# TC37X register map
File version: 1.0.0
CPU: CM4 r0p1, little endian, MPU, FPU, VTOR, 3 interrupt priority bits
Registers are 16-bit, read-write, reset 0x0 unless marked. A register's access mark holds for its fields unless they carry their own. Offsets are from the block's base; [hi:lo] are bit positions; {n}, {i} and the like mark numbered series; 'fields as' and 'values as' point back to an identical list.

## EVADC — ce_evadc
Base 0xF0020000
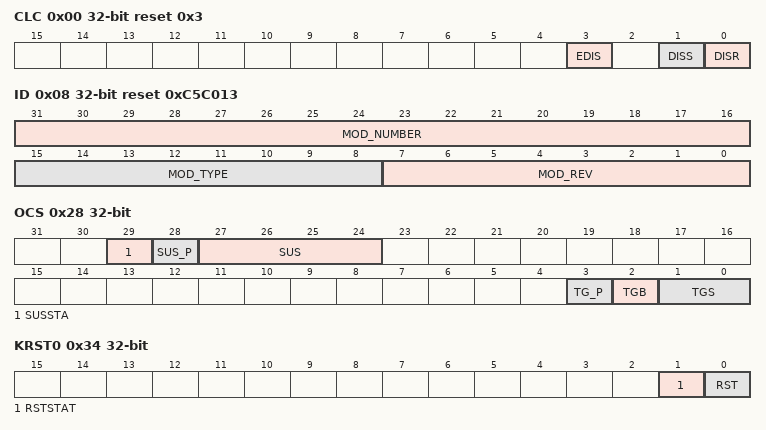
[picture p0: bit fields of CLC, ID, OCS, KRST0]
0x00 CLC 32-bit reset 0x3 — Clock Control Register
  [3] EDIS — Sleep Mode Enable Control - EDIS
  [1] DISS ro — Module Disable Status Bit - DISS
  [0] DISR — Module Disable Request Bit - DISR
0x08 ID 32-bit ro reset 0xC5C013 — Module Identification Register
  [31:16] MOD_NUMBER — Module Number - MOD_NUMBER
  [15:8] MOD_TYPE — Module Type - MOD_TYPE
  [7:0] MOD_REV — Module Revision - MOD_REV
0x28 OCS 32-bit — OCDS Control and Status Register
  [29] SUSSTA ro — Suspend State - SUSSTA
  [28] SUS_P wo — SUS Write Protection - SUS_P
  [27:24] SUS — OCDS Suspend Control - SUS
  [3] TG_P wo — TGS, TGB Write Protection - TG_P
  [2] TGB — OTGB0/1 Bus Select - TGB
  [1:0] TGS — Trigger Set for OTGB0/1 - TGS
0x2C KRSTCLR 32-bit wo — Kernel Reset Status Clear Register
  [0] CLR — Kernel Reset Status Clear - CLR
0x30 KRST1 32-bit — Kernel Reset Register 1
  [0] RST — Kernel Reset - RST
0x34 KRST0 32-bit — Kernel Reset Register 0
  [1] RSTSTAT ro — Kernel Reset Status - RSTSTAT
  [0] RST — Kernel Reset - RST
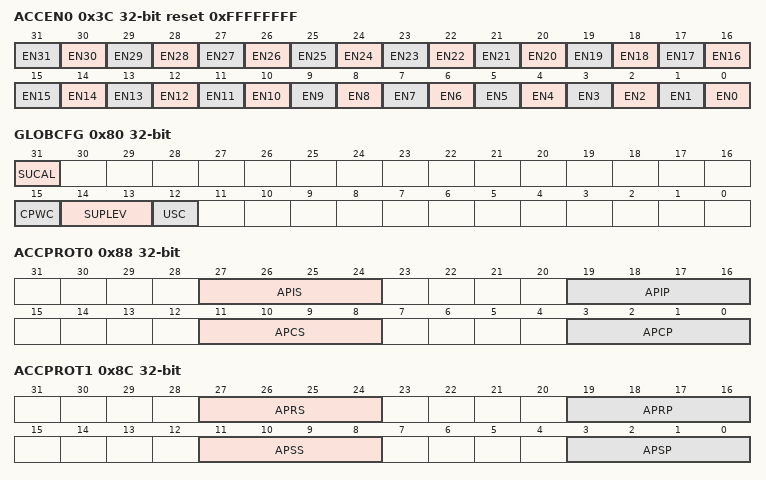
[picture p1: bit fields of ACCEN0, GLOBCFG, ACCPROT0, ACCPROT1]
0x3C ACCEN0 32-bit reset 0xFFFFFFFF — Access Enable Register 0
  [n] EN{n} (n=0..31) — Access Enable for Master TAG ID {n} - EN{n}
0x80 GLOBCFG 32-bit — Global Configuration Register
  [31] SUCAL wo — Start-Up Calibration - SUCAL
  [15] CPWC wo — Write Control for Control Parameters - CPWC
  [14:13] SUPLEV — Supply Voltage Level - SUPLEV
  [12] USC — Unsynchronized Clock Generation - USC
0x88 ACCPROT0 32-bit — Access Protection Register 0
  [27:24] APIS — Access Protection Initialization, Secondary Groups
  [19:16] APIP — Access Protection Initialization, Primary Groups
  [11:8] APCS — Access Protection Channel Control, Secondary Groups
  [3:0] APCP — Access Protection Channel Control, Primary Groups
0x8C ACCPROT1 32-bit — Access Protection Register 1
  [27:24] APRS — Access Protection Result Registers, Secondary Groups
  [19:16] APRP — Access Protection Result Registers, Primary Groups
  [11:8] APSS — Access Protection Service Request, Secondary Groups
  [3:0] APSP — Access Protection Service Request, Primary Groups
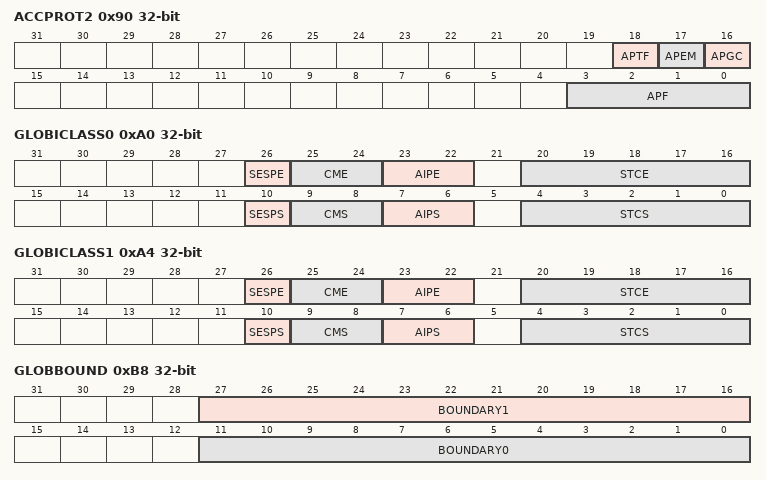
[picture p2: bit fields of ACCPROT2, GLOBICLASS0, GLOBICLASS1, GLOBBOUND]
0x90 ACCPROT2 32-bit — Access Protection Register 2
  [18] APTF — Access Protection Test Function - APTF
  [17] APEM — Access Protection External Multiplexer - APEM
  [16] APGC — Access Protection Global Configuration - APGC
  [3:0] APF — Access Protection Fast Compare Channels
0xA0 GLOBICLASS0 32-bit — Input Class Register 0, Global
  [26] SESPE — Spread Early Sample Point for EMUX Conversions - SESPE
  [25:24] CME — Conversion Mode for EMUX Conversions - CME
  [23:22] AIPE — Analog Input Precharge Control for EMUX Conversions - AIPE
  [20:16] STCE — Sample Time Control for EMUX Conversions - STCE
  [10] SESPS — Spread Early Sample Point for Standard Conversions - SESPS
  [9:8] CMS — Conversion Mode for Standard Conversions - CMS
  [7:6] AIPS — Analog Input Precharge Control for Standard Conversions - AIPS
  [4:0] STCS — Sample Time Control for Standard Conversions - STCS
0xA4 GLOBICLASS1 32-bit — Input Class Register 1, Global
  fields as GLOBICLASS0
0xB8 GLOBBOUND 32-bit — Global Boundary Select Register
  [27:16] BOUNDARY1 — Boundary Value 1 for Limit Checking - BOUNDARY1
  [11:0] BOUNDARY0 — Boundary Value 0 for Limit Checking - BOUNDARY0
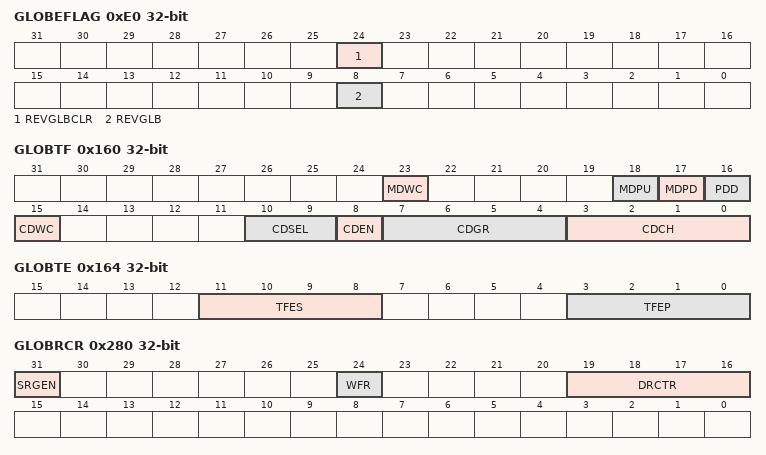
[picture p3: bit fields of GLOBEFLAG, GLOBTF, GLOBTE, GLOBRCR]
0xE0 GLOBEFLAG 32-bit — Global Event Flag Register
  [24] REVGLBCLR wo — Clear Global Result Event - REVGLBCLR
  [8] REVGLB — Global Result Event - REVGLB
0x140 GLOBEVNP 32-bit — Global Event Node Pointer Register
  [19:16] REV0NP — Service Request Node Pointer Global Result
0x160 GLOBTF 32-bit — Global Test Functions Register
  [23] MDWC wo — Write Control for Multiplexer Diagnostics - MDWC
  [18] MDPU — Multiplexer Diagnostics Pull-Up-Devices Enable
  [17] MDPD — Multiplexer Diagnostics Pull-Down-Devices Enable
  [16] PDD — Pull-Down Diagnostics Enable - PDD
  [15] CDWC wo — Write Control for Conversion Diagnostics - CDWC
  [10:9] CDSEL — Converter Diagnostics Pull-Devices Select - CDSEL
  [8] CDEN — Converter Diagnostics Enable - CDEN
  [7:4] CDGR — Conversion Diagnostics Group - CDGR
  [3:0] CDCH — Conversion Diagnostics Channel - CDCH
0x164 GLOBTE 32-bit — Global Test Enable Register
  [11:8] TFES — Test Function Enable, Secondary Groups
  [3:0] TFEP — Test Function Enable, Primary Groups
0x280 GLOBRCR 32-bit — Global Result Control Register
  [31] SRGEN — Service Request Generation Enable - SRGEN
  [24] WFR — Wait-for-Read Mode Enable - WFR
  [19:16] DRCTR — Data Reduction Control - DRCTR
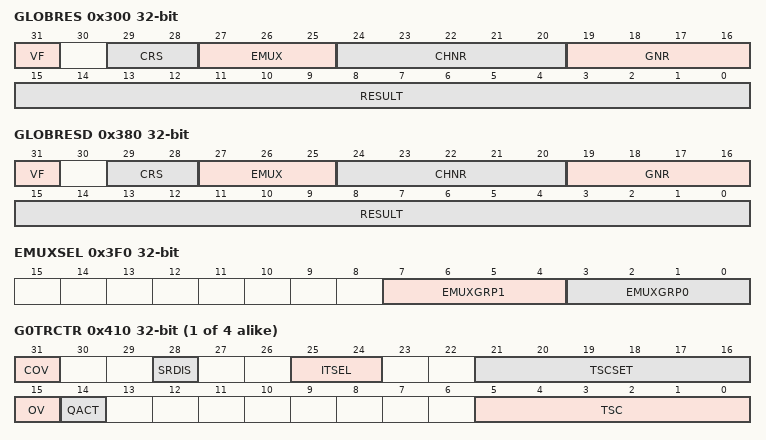
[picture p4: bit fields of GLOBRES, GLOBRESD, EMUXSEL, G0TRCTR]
0x300 GLOBRES 32-bit — Global Result Register
  [31] VF — Valid Flag - VF
  [29:28] CRS ro — Converted Request Source - CRS
  [27:25] EMUX ro — External Multiplexer Setting - EMUX
  [24:20] CHNR ro — Channel Number - CHNR
  [19:16] GNR ro — Group Number - GNR
  [15:0] RESULT — Result of most recent conversion - RESULT
0x380 GLOBRESD 32-bit ro — Global Result Register, Debug
  [31] VF — Valid Flag - VF
  [29:28] CRS — Converted Request Source - CRS
  [27:25] EMUX — External Multiplexer Setting - EMUX
  [24:20] CHNR — Channel Number - CHNR
  [19:16] GNR — Group Number - GNR
  [15:0] RESULT — Result of most recent conversion - RESULT
0x3F0 EMUXSEL 32-bit — External Multiplexer Interface Select Register
  [7:4] EMUXGRP1 — External Multiplexer Group for Interface 1
  [3:0] EMUXGRP0 — External Multiplexer Group for Interface 0
{0x410+0x400*i} G{i}TRCTR 32-bit (i=0..3) — Trigger Control Register, Group {i}
  [31] COV wo — Clear Overflow Flag - COV
  [28] SRDIS — Service Request Disable - SRDIS
  [25:24] ITSEL — Internal Trigger Input Selection - ITSEL
  [21:16] TSCSET — Trigger Sequence Counter Start Value - TSCSET
  [15] OV ro — Overflow Detected - OV
  [14] QACT ro — Queue Active - QACT
  [5:0] TSC ro — Trigger Sequence Counter - TSC
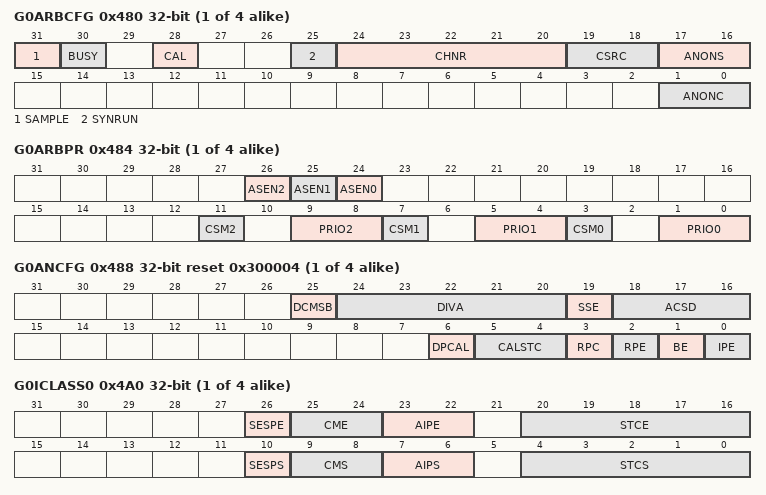
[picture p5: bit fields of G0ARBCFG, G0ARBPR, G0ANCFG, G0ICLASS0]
{0x480+0x400*i} G{i}ARBCFG 32-bit (i=0..3) — Arbitration Config. Register, Group {i}
  [31] SAMPLE ro — Sample Phase Flag - SAMPLE
  [30] BUSY ro — Converter Busy Flag - BUSY
  [28] CAL ro — Start-Up Calibration Active Indication - CAL
  [25] SYNRUN ro — Synchronous Conversion Running - SYNRUN
  [24:20] CHNR ro — Channel Number - CHNR
  [19:18] CSRC ro — Currently Converted Request Source - CSRC
  [17:16] ANONS ro — Analog Converter Control Status - ANONS
  [1:0] ANONC — Analog Converter Control - ANONC
{0x484+0x400*i} G{i}ARBPR 32-bit (i=0..3) — Arbitration Priority Register, Group {i}
  [26] ASEN2 — Arbitration Source Input 2 Enable
  [25] ASEN1 — Arbitration Source Input 1 Enable
  [24] ASEN0 — Arbitration Source Input 0 Enable
  [11] CSM2 — Conversion Start Mode of Request Source 2
  [9:8] PRIO2 — Priority of Request Source i
  [7] CSM1 — Conversion Start Mode of Request Source 1
  [5:4] PRIO1 — Priority of Request Source i
  [3] CSM0 — Conversion Start Mode of Request Source 0
  [1:0] PRIO0 — Priority of Request Source i
{0x488+0x400*i} G{i}ANCFG 32-bit reset 0x300004 (i=0..3) — Analog Fct. Config. Register, Group {i}
  [25] DCMSB — Double Clock for the MSB Conversion - DCMSB
  [24:20] DIVA — Divider Factor for the Analog Internal Clock - DIVA
  [19] SSE — Sample Synchronization Enable - SSE
  [18:16] ACSD — Analog Clock Synchronization Delay - ACSD
  [6] DPCAL — Disable Post-Calibration - DPCAL
  [5:4] CALSTC — Calibration Sample Time Control - CALSTC
  [3] RPC — Reference Precharge Control - RPC
  [2] RPE — Reference Precharge Enable - RPE
  [1] BE — Input Buffer Enable - BE
  [0] IPE — Idle Precharge Enable - IPE
{0x4A0+0x400*i} G{i}ICLASS0 32-bit (i=0..3) — Input Class Register 0, Group {i}
  fields as GLOBICLASS0
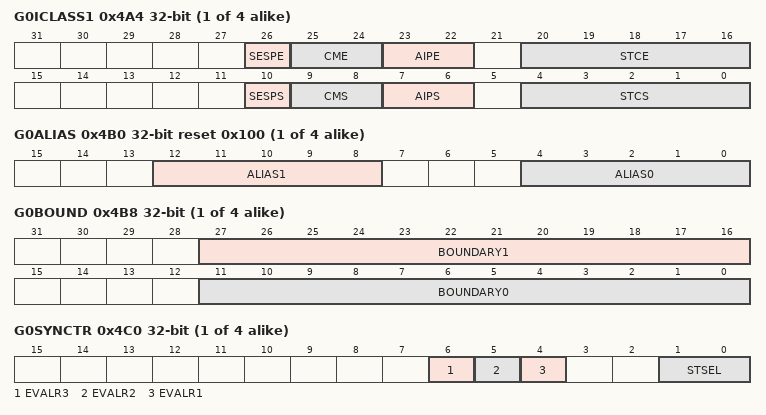
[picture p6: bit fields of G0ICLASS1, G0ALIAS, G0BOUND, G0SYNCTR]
{0x4A4+0x400*i} G{i}ICLASS1 32-bit (i=0..3) — Input Class Register 1, Group {i}
  fields as GLOBICLASS0
{0x4B0+0x400*i} G{i}ALIAS 32-bit reset 0x100 (i=0..3) — Alias Register, Group {i}
  [12:8] ALIAS1 — Alias Value for CH1 Conversion Requests - ALIAS1
  [4:0] ALIAS0 — Alias Value for CH0 Conversion Requests - ALIAS0
{0x4B8+0x400*i} G{i}BOUND 32-bit (i=0..3) — Boundary Select Register, Group {i}
  fields as GLOBBOUND
{0x4C0+0x400*i} G{i}SYNCTR 32-bit (i=0..3) — Synchronization Control Register, Group {i}
  [6] EVALR3 — Evaluate Ready Input Ri
  [5] EVALR2 — Evaluate Ready Input Ri
  [4] EVALR1 — Evaluate Ready Input Ri
  [1:0] STSEL — Start Selection - STSEL
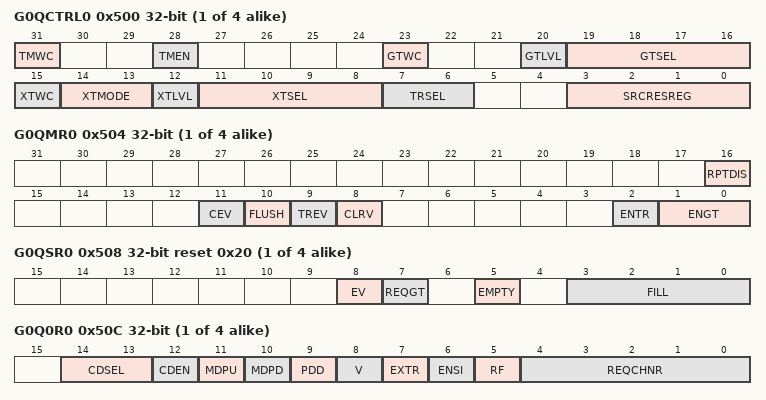
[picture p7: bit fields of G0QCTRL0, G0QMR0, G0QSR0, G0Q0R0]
{0x500+0x400*i} G{i}QCTRL0 32-bit (i=0..3) — Queue 0 Source Contr. Register, Group {i}
  [31] TMWC wo — Write Control for Timer Mode - TMWC
  [28] TMEN — Timer Mode Enable - TMEN
  [23] GTWC wo — Write Control for Gate Configuration - GTWC
  [20] GTLVL ro — Gate Input Level - GTLVL
  [19:16] GTSEL — Gate Input Selection - GTSEL
  [15] XTWC wo — Write Control for Trigger Configuration - XTWC
  [14:13] XTMODE — Trigger Operating Mode - XTMODE
  [12] XTLVL ro — External Trigger Level - XTLVL
  [11:8] XTSEL — External Trigger Input Selection - XTSEL
  [7:6] TRSEL — Trigger Source Selection - TRSEL
  [3:0] SRCRESREG — Source-specific Result Register - SRCRESREG
{0x504+0x400*i} G{i}QMR0 32-bit (i=0..3) — Queue 0 Mode Register, Group {i}
  [16] RPTDIS — Repeat Disable - RPTDIS
  [11] CEV wo — Clear Event Flag - CEV
  [10] FLUSH wo — Flush Queue - FLUSH
  [9] TREV wo — Trigger Event - TREV
  [8] CLRV wo — Clear Valid Bit - CLRV
  [2] ENTR — Enable External Trigger - ENTR
  [1:0] ENGT — Enable Gate - ENGT
{0x508+0x400*i} G{i}QSR0 32-bit ro reset 0x20 (i=0..3) — Queue 0 Status Register, Group {i}
  [8] EV — Event Detected - EV
  [7] REQGT — Request Gate Level - REQGT
  [5] EMPTY — Queue Empty - EMPTY
  [3:0] FILL — Filling Level for Queue - FILL
{0x50C+0x400*i} G{i}Q0R0 32-bit ro (i=0..3) — Queue 0 Register 0, Group {i}
  [14:13] CDSEL — Converter Diagnostics Pull-Devices Select - CDSEL
  [12] CDEN — Converter Diagnostics Enable - CDEN
  [11] MDPU — Multiplexer Diagnostics Pull-Devices Enable - MDPD,MDPU
  [10] MDPD — Multiplexer Diagnostics Pull-Devices Enable - MDPD,MDPU
  [9] PDD — Pull-Down Diagnostics Enable - PDD
  [8] V — Request Channel Number Valid - V
  [7] EXTR — External Trigger - EXTR
  [6] ENSI — Enable Source Interrupt - ENSI
  [5] RF — Refill - RF
  [4:0] REQCHNR — Request Channel Number - REQCHNR
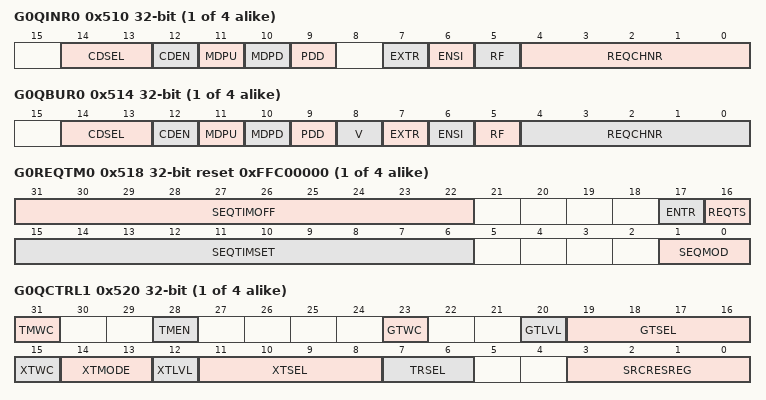
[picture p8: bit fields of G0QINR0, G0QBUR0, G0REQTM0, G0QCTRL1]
{0x510+0x400*i} G{i}QINR0 32-bit wo (i=0..3) — Queue 0 Input Register, Group {i}
  [14:13] CDSEL — Converter Diagnostics Pull-Devices Select - CDSEL
  [12] CDEN — Converter Diagnostics Enable - CDEN
  [11] MDPU — Multiplexer Diagnostics Pull-Devices Enable - MDPD,MDPU
  [10] MDPD — Multiplexer Diagnostics Pull-Devices Enable - MDPD,MDPU
  [9] PDD — Pull-Down Diagnostics Enable - PDD
  [7] EXTR — External Trigger - EXTR
  [6] ENSI — Enable Source Interrupt - ENSI
  [5] RF — Refill - RF
  [4:0] REQCHNR — Request Channel Number - REQCHNR
{0x514+0x400*i} G{i}QBUR0 32-bit ro (i=0..3) — Queue 0 Backup Register, Group {i}
  [14:13] CDSEL — Converter Diagnostics Pull-Devices Select - CDSEL
  [12] CDEN — Converter Diagnostics Enable - CDEN
  [11] MDPU — Multiplexer Diagnostics Pull-Up Devices Enable
  [10] MDPD — Multiplexer Diagnostics Pull-Down Devices Enable
  [9] PDD — Pull-Down Diagnostics Enable - PDD
  [8] V — Request Channel Number Valid - V
  [7] EXTR — External Trigger - EXTR
  [6] ENSI — Enable Source Interrupt - ENSI
  [5] RF — Refill - RF
  [4:0] REQCHNR — Request Channel Number - REQCHNR
{0x518+0x400*i} G{i}REQTM0 32-bit reset 0xFFC00000 (i=0..3) — Queue 0 Requ. Timer Mode Reg., Group {i}
  [31:22] SEQTIMOFF — Sequence Timer, Switch Off Value - SEQTIMOFF
  [17] ENTR — Enable External Trigger - ENTR
  [16] REQTS wo — Request Timer Start Trigger - REQTS
  [15:6] SEQTIMSET — Sequence Timer, Set Value - SEQTIMSET
  [1:0] SEQMOD — Sequence Mode - SEQMOD
{0x51C+0x400*i} G{i}REQTS0 32-bit ro (i=0..3) — Queue 0 Requ. Timer Status Reg., Group {i}
  [15:6] SEQTIMER — Sequence Timer - SEQTIMER
{0x520+0x400*i} G{i}QCTRL1 32-bit (i=0..3) — Queue 1 Source Contr. Register, Group {i}
  fields as G0QCTRL0
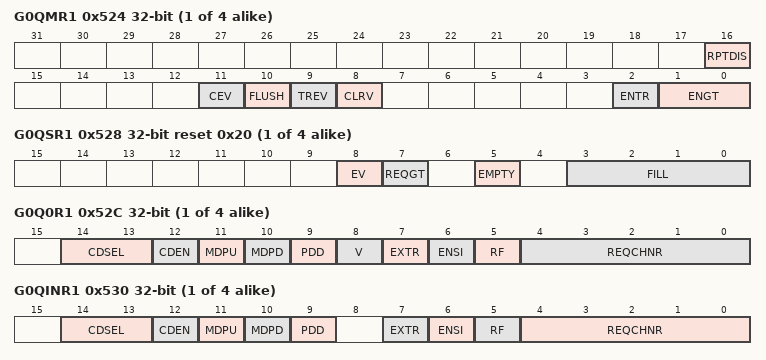
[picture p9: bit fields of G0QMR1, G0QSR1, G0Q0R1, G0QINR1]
{0x524+0x400*i} G{i}QMR1 32-bit (i=0..3) — Queue 1 Mode Register, Group {i}
  fields as G0QMR0
{0x528+0x400*i} G{i}QSR1 32-bit ro reset 0x20 (i=0..3) — Queue 1 Status Register, Group {i}
  fields as G0QSR0
{0x52C+0x400*i} G{i}Q0R1 32-bit ro (i=0..3) — Queue 1 Register 0, Group {i}
  fields as G0Q0R0
{0x530+0x400*i} G{i}QINR1 32-bit wo (i=0..3) — Queue 1 Input Register, Group {i}
  fields as G0QINR0
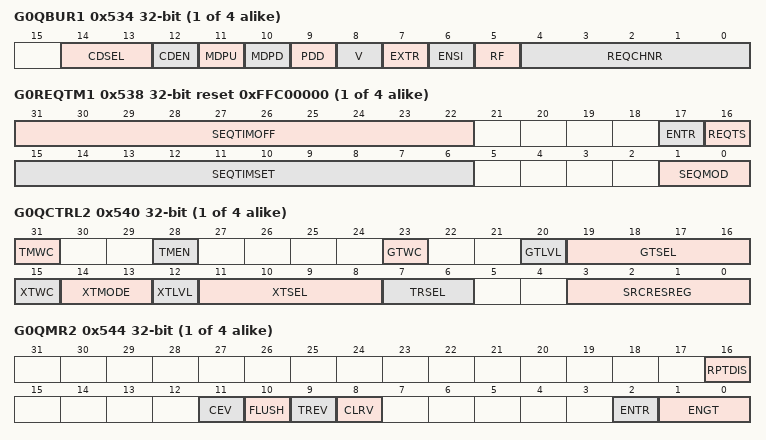
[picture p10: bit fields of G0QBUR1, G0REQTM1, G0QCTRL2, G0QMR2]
{0x534+0x400*i} G{i}QBUR1 32-bit ro (i=0..3) — Queue 1 Backup Register, Group {i}
  fields as G0QBUR0
{0x538+0x400*i} G{i}REQTM1 32-bit reset 0xFFC00000 (i=0..3) — Queue 1 Requ. Timer Mode Reg., Group {i}
  fields as G0REQTM0
{0x53C+0x400*i} G{i}REQTS1 32-bit ro (i=0..3) — Queue 1 Requ. Timer Status Reg., Group {i}
  [15:6] SEQTIMER — Sequence Timer - SEQTIMER
{0x540+0x400*i} G{i}QCTRL2 32-bit (i=0..3) — Queue 2 Source Contr. Register, Group {i}
  fields as G0QCTRL0
{0x544+0x400*i} G{i}QMR2 32-bit (i=0..3) — Queue 2 Mode Register, Group {i}
  fields as G0QMR0
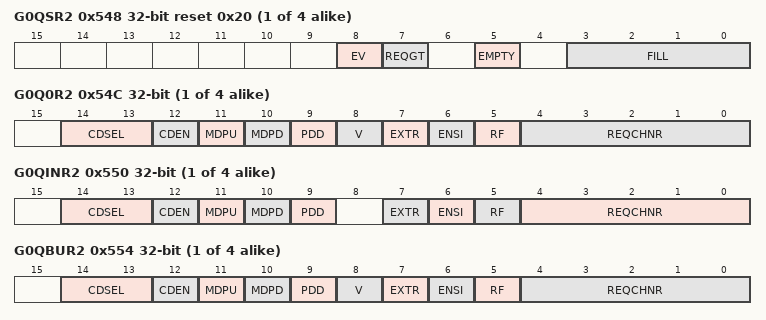
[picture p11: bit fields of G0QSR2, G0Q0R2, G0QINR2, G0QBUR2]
{0x548+0x400*i} G{i}QSR2 32-bit ro reset 0x20 (i=0..3) — Queue 2 Status Register, Group {i}
  fields as G0QSR0
{0x54C+0x400*i} G{i}Q0R2 32-bit ro (i=0..3) — Queue 2 Register 0, Group {i}
  fields as G0Q0R0
{0x550+0x400*i} G{i}QINR2 32-bit wo (i=0..3) — Queue 2 Input Register, Group {i}
  fields as G0QINR0
{0x554+0x400*i} G{i}QBUR2 32-bit ro (i=0..3) — Queue 2 Backup Register, Group {i}
  fields as G0QBUR0
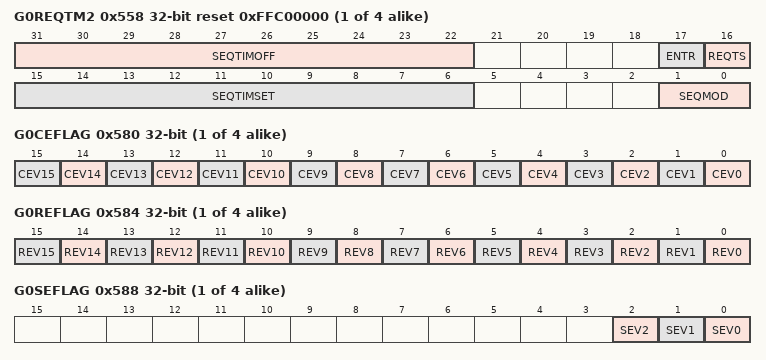
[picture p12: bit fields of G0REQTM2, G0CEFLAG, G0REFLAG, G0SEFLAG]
{0x558+0x400*i} G{i}REQTM2 32-bit reset 0xFFC00000 (i=0..3) — Queue 2 Requ. Timer Mode Reg., Group {i}
  fields as G0REQTM0
{0x55C+0x400*i} G{i}REQTS2 32-bit ro (i=0..3) — Queue 2 Requ. Timer Status Reg., Group {i}
  [15:6] SEQTIMER — Sequence Timer - SEQTIMER
{0x580+0x400*i} G{i}CEFLAG 32-bit (i=0..3) — Channel Event Flag Register, Group {i}
  [n] CEV{n} (n=0..15) — Channel Event for Channel {n}
{0x584+0x400*i} G{i}REFLAG 32-bit (i=0..3) — Result Event Flag Register, Group {i}
  [n] REV{n} (n=0..15) — Result Event for Result Register {n}
{0x588+0x400*i} G{i}SEFLAG 32-bit (i=0..3) — Source Event Flag Register, Group {i}
  [2] SEV2 — Source Event i
  [1] SEV1 — Source Event i
  [0] SEV0 — Source Event i
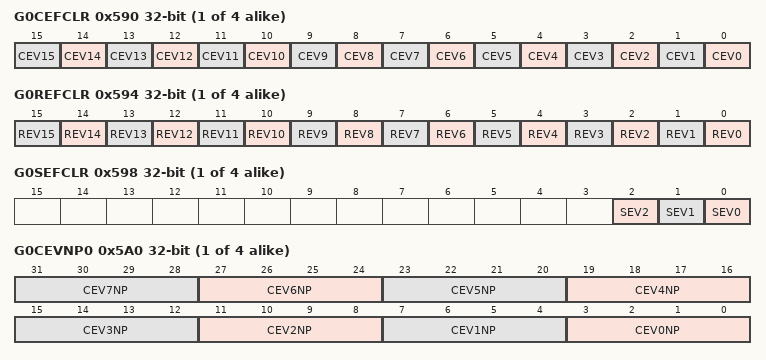
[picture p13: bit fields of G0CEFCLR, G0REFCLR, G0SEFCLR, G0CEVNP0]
{0x590+0x400*i} G{i}CEFCLR 32-bit wo (i=0..3) — Channel Event Flag Clear Register, Group {i}
  [n] CEV{n} (n=0..15) — Clear Channel Event for Channel {n} - CEV{n}
{0x594+0x400*i} G{i}REFCLR 32-bit wo (i=0..3) — Result Event Flag Clear Register, Group {i}
  [n] REV{n} (n=0..15) — Clear Result Event for Result Register {n}
{0x598+0x400*i} G{i}SEFCLR 32-bit wo (i=0..3) — Source Event Flag Clear Reg., Group {i}
  [2] SEV2 — Clear Source Event i
  [1] SEV1 — Clear Source Event i
  [0] SEV0 — Clear Source Event i
{0x5A0+0x400*i} G{i}CEVNP0 32-bit (i=0..3) — Channel Event Node Pointer Reg. 0, Group {i}
  [4n+3:4n] CEV{n}NP (n=0..7) — Service Request Node Pointer Channel Event i
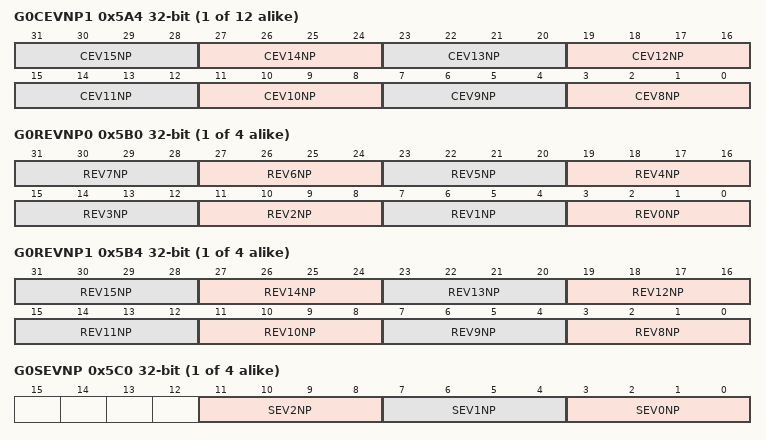
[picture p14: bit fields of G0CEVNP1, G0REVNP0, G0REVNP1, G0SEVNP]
{0x5A4+0x400*i} G{i}CEVNP1 32-bit (i=0..11) — Channel Event Node Pointer Reg. 1, Group {i}
  [4n-29:4n-32] CEV{n}NP (n=8..15) — Service Request Node Pointer Channel Event i
{0x5B0+0x400*i} G{i}REVNP0 32-bit (i=0..3) — Result Event Node Pointer Reg. 0, Group {i}
  [4n+3:4n] REV{n}NP (n=0..7) — Service Request Node Pointer Result Event i
{0x5B4+0x400*i} G{i}REVNP1 32-bit (i=0..3) — Result Event Node Pointer Reg. 1, Group {i}
  [4n-29:4n-32] REV{n}NP (n=8..15) — Service Request Node Pointer Result Event i
{0x5C0+0x400*i} G{i}SEVNP 32-bit (i=0..3) — Source Event Node Pointer Reg., Group {i}
  [11:8] SEV2NP — Service Request Node Pointer Source Event i
  [7:4] SEV1NP — Service Request Node Pointer Source Event i
  [3:0] SEV0NP — Service Request Node Pointer Source Event i
{0x5C8+0x400*i} G{i}SRACT 32-bit wo (i=0..3) — Service Request Software Activation Trigger, Group {i}
  [n+8] ASSR{n} (n=0..3) — Activate Shared Service Request Node {n} - ASSR{n}
  [n] AGSR{n} (n=0..3) — Activate Group Service Request Node {n} - AGSR{n}
{0x5F0+0x400*i} G{i}EMUXCTR 32-bit (i=0..3) — External Multiplexer Control Reg., Group {i}
  [24:20] EMUXCCB — External Multiplexer Channel Selection for Block Mode - EMUXCCB
  [18:16] EMUXACT ro — External Multiplexer Actual Selection - EMUXACT
  [15] EMXWC wo — Write Control for EMUX Configuration - EMXWC
  [14] EMXCSS — External Multiplexer Channel Selection Style - EMXCSS
  [13] EMXST — External Multiplexer Sample Time Control - EMXST
  [12] EMXCOD — External Multiplexer Coding Scheme - EMXCOD
  [6:4] EMUXMODE — External Multiplexer Mode - EMUXMODE
  [2:0] EMUXSET — External Multiplexer Start Selection - EMUXSET
{0x5F4+0x400*i} G{i}EMUXCS 32-bit (i=0..3) — Ext. Multiplexer Channel Select Reg., Group {i}
  [15:0] EMUXCH — External Multiplexer Channel Select - EMUXCH
{0x5F8+0x400*i} G{i}VFR 32-bit (i=0..3) — Valid Flag Register, Group {i}
  [n] VF{n} (n=0..15) — Valid Flag of Result Register x - VF{n}
{0x600+4i} G0CHCTR{i} 32-bit (i=0..7) — Group 0, Channel {i} Control Register
  [30] BWDEN — Broken Wire Detection Enable - BWDEN
  [29:28] BWDCH — Broken Wire Detection Channel - BWDCH
  [21] RESPOS — Result Position - RESPOS
  [20] RESTGT — Result Target - RESTGT
  [19:16] RESREG — Result Register - RESREG
  [15:12] BNDSELX — BoundaryExtension - BNDSELX
  [11] REFSEL — Reference Input Selection - REFSEL
  [10] SYNC — Synchronization Request - SYNC
  [9:8] CHEVMODE — Channel Event Mode - CHEVMODE
  [7:6] BNDSELU — Upper Boundary Select - BNDSELU
  [5:4] BNDSELL — Lower Boundary Select - BNDSELL
  [1:0] ICLSEL — Input Class Select - ICLSEL
{0x680+4i} G0RCR{i} 32-bit (i=0..15) — Group 0 Result Control Register {i}
  [31] SRGEN — Service Request Generation Enable - SRGEN
  [26:25] FEN — FIFO Mode Enable - FEN
  [24] WFR — Wait-for-Read Mode Enable - WFR
  [21:20] DMM — Data Modification Mode - DMM
  [19:16] DRCTR — Data Reduction Control - DRCTR
{0x700+4i} G0RES{i} 32-bit (i=0..15) — Group 0 Result Register {i}
  [31] VF ro — Valid Flag - VF
  [29:28] CRS ro — Converted Request Source - CRS
  [27:25] EMUX ro — External Multiplexer Setting - EMUX
  [24:20] CHNR ro — Channel Number - CHNR
  [19:16] DRC ro — Data Reduction Counter - DRC
  [15:0] RESULT — Result of Most Recent Conversion - RESULT
{0x780+4i} G0RESD{i} 32-bit ro (i=0..15) — Group 0 Result Reg. {i}, Debug
  [31] VF — Valid Flag - VF
  [29:28] CRS — Converted Request Source - CRS
  [27:25] EMUX — External Multiplexer Setting - EMUX
  [24:20] CHNR — Channel Number - CHNR
  [19:16] DRC — Data Reduction Counter - DRC
  [15:0] RESULT — Result of Most Recent Conversion - RESULT
{0xA00+4i} G1CHCTR{i} 32-bit (i=0..7) — Group 1, Channel {i} Control Register
  fields as G0CHCTR0
{0xA80+4i} G1RCR{i} 32-bit (i=0..15) — Group 1 Result Control Register {i}
  fields as G0RCR0
{0xB00+4i} G1RES{i} 32-bit (i=0..15) — Group 1 Result Register {i}
  fields as G0RES0
{0xB80+4i} G1RESD{i} 32-bit ro (i=0..15) — Group 1 Result Reg. {i}, Debug
  fields as G0RESD0
{0xE00+4i} G2CHCTR{i} 32-bit (i=0..7) — Group 2, Channel {i} Control Register
  fields as G0CHCTR0
{0xE80+4i} G2RCR{i} 32-bit (i=0..15) — Group 2 Result Control Register {i}
  fields as G0RCR0
{0xF00+4i} G2RES{i} 32-bit (i=0..15) — Group 2 Result Register {i}
  fields as G0RES0
{0xF80+4i} G2RESD{i} 32-bit ro (i=0..15) — Group 2 Result Reg. {i}, Debug
  fields as G0RESD0
{0x1200+4i} G3CHCTR{i} 32-bit (i=0..7) — Group 3, Channel {i} Control Register
  fields as G0CHCTR0
{0x1280+4i} G3RCR{i} 32-bit (i=0..15) — Group 3 Result Control Register {i}
  fields as G0RCR0
{0x1300+4i} G3RES{i} 32-bit (i=0..15) — Group 3 Result Register {i}
  fields as G0RES0
{0x1380+4i} G3RESD{i} 32-bit ro (i=0..15) — Group 3 Result Reg. {i}, Debug
  fields as G0RESD0
{0x410+0x400*i} G{i}TRCTR 32-bit (i=8..11) — Trigger Control Register, Group {i}
  fields as G0TRCTR
{0x480+0x400*i} G{i}ARBCFG 32-bit (i=8..11) — Arbitration Config. Register, Group {i}
  fields as G0ARBCFG
{0x484+0x400*i} G{i}ARBPR 32-bit (i=8..11) — Arbitration Priority Register, Group {i}
  fields as G0ARBPR
{0x488+0x400*i} G{i}ANCFG 32-bit reset 0x300004 (i=8..11) — Analog Fct. Config. Register, Group {i}
  fields as G0ANCFG
{0x4A0+0x400*i} G{i}ICLASS0 32-bit (i=8..11) — Input Class Register 0, Group {i}
  fields as GLOBICLASS0
{0x4A4+0x400*i} G{i}ICLASS1 32-bit (i=8..11) — Input Class Register 1, Group {i}
  fields as GLOBICLASS0
{0x4B0+0x400*i} G{i}ALIAS 32-bit reset 0x100 (i=8..11) — Alias Register, Group {i}
  fields as G0ALIAS
{0x4B8+0x400*i} G{i}BOUND 32-bit (i=8..11) — Boundary Select Register, Group {i}
  fields as GLOBBOUND
{0x4C0+0x400*i} G{i}SYNCTR 32-bit (i=8..11) — Synchronization Control Register, Group {i}
  fields as G0SYNCTR
{0x500+0x400*i} G{i}QCTRL0 32-bit (i=8..11) — Queue 0 Source Contr. Register, Group {i}
  fields as G0QCTRL0
{0x504+0x400*i} G{i}QMR0 32-bit (i=8..11) — Queue 0 Mode Register, Group {i}
  fields as G0QMR0
{0x508+0x400*i} G{i}QSR0 32-bit ro reset 0x20 (i=8..11) — Queue 0 Status Register, Group {i}
  fields as G0QSR0
{0x50C+0x400*i} G{i}Q0R0 32-bit ro (i=8..11) — Queue 0 Register 0, Group {i}
  fields as G0Q0R0
{0x510+0x400*i} G{i}QINR0 32-bit wo (i=8..11) — Queue 0 Input Register, Group {i}
  fields as G0QINR0
{0x514+0x400*i} G{i}QBUR0 32-bit ro (i=8..11) — Queue 0 Backup Register, Group {i}
  fields as G0QBUR0
{0x518+0x400*i} G{i}REQTM0 32-bit reset 0xFFC00000 (i=8..11) — Queue 0 Requ. Timer Mode Reg., Group {i}
  fields as G0REQTM0
{0x51C+0x400*i} G{i}REQTS0 32-bit ro (i=8..11) — Queue 0 Requ. Timer Status Reg., Group {i}
  [15:6] SEQTIMER — Sequence Timer - SEQTIMER
{0x520+0x400*i} G{i}QCTRL1 32-bit (i=8..11) — Queue 1 Source Contr. Register, Group {i}
  fields as G0QCTRL0
{0x524+0x400*i} G{i}QMR1 32-bit (i=8..11) — Queue 1 Mode Register, Group {i}
  fields as G0QMR0
{0x528+0x400*i} G{i}QSR1 32-bit ro reset 0x20 (i=8..11) — Queue 1 Status Register, Group {i}
  fields as G0QSR0
{0x52C+0x400*i} G{i}Q0R1 32-bit ro (i=8..11) — Queue 1 Register 0, Group {i}
  fields as G0Q0R0
{0x530+0x400*i} G{i}QINR1 32-bit wo (i=8..11) — Queue 1 Input Register, Group {i}
  fields as G0QINR0
{0x534+0x400*i} G{i}QBUR1 32-bit ro (i=8..11) — Queue 1 Backup Register, Group {i}
  fields as G0QBUR0
{0x538+0x400*i} G{i}REQTM1 32-bit reset 0xFFC00000 (i=8..11) — Queue 1 Requ. Timer Mode Reg., Group {i}
  fields as G0REQTM0
{0x53C+0x400*i} G{i}REQTS1 32-bit ro (i=8..11) — Queue 1 Requ. Timer Status Reg., Group {i}
  [15:6] SEQTIMER — Sequence Timer - SEQTIMER
{0x540+0x400*i} G{i}QCTRL2 32-bit (i=8..11) — Queue 2 Source Contr. Register, Group {i}
  fields as G0QCTRL0
{0x544+0x400*i} G{i}QMR2 32-bit (i=8..11) — Queue 2 Mode Register, Group {i}
  fields as G0QMR0
{0x548+0x400*i} G{i}QSR2 32-bit ro reset 0x20 (i=8..11) — Queue 2 Status Register, Group {i}
  fields as G0QSR0
{0x54C+0x400*i} G{i}Q0R2 32-bit ro (i=8..11) — Queue 2 Register 0, Group {i}
  fields as G0Q0R0
{0x550+0x400*i} G{i}QINR2 32-bit wo (i=8..11) — Queue 2 Input Register, Group {i}
  fields as G0QINR0
{0x554+0x400*i} G{i}QBUR2 32-bit ro (i=8..11) — Queue 2 Backup Register, Group {i}
  fields as G0QBUR0
{0x558+0x400*i} G{i}REQTM2 32-bit reset 0xFFC00000 (i=8..11) — Queue 2 Requ. Timer Mode Reg., Group {i}
  fields as G0REQTM0
{0x55C+0x400*i} G{i}REQTS2 32-bit ro (i=8..11) — Queue 2 Requ. Timer Status Reg., Group {i}
  [15:6] SEQTIMER — Sequence Timer - SEQTIMER
{0x580+0x400*i} G{i}CEFLAG 32-bit (i=8..11) — Channel Event Flag Register, Group {i}
  [n] CEV{n} (n=0..15) — Channel Event for Channel {n}
{0x584+0x400*i} G{i}REFLAG 32-bit (i=8..11) — Result Event Flag Register, Group {i}
  [n] REV{n} (n=0..15) — Result Event for Result Register {n}
{0x588+0x400*i} G{i}SEFLAG 32-bit (i=8..11) — Source Event Flag Register, Group {i}
  fields as G0SEFLAG
{0x590+0x400*i} G{i}CEFCLR 32-bit wo (i=8..11) — Channel Event Flag Clear Register, Group {i}
  [n] CEV{n} (n=0..15) — Clear Channel Event for Channel {n} - CEV{n}
{0x594+0x400*i} G{i}REFCLR 32-bit wo (i=8..11) — Result Event Flag Clear Register, Group {i}
  [n] REV{n} (n=0..15) — Clear Result Event for Result Register {n}
{0x598+0x400*i} G{i}SEFCLR 32-bit wo (i=8..11) — Source Event Flag Clear Reg., Group {i}
  fields as G0SEFCLR
{0x5A0+0x400*i} G{i}CEVNP0 32-bit (i=8..11) — Channel Event Node Pointer Reg. 0, Group {i}
  fields as G0CEVNP0
{0x5B0+0x400*i} G{i}REVNP0 32-bit (i=8..11) — Result Event Node Pointer Reg. 0, Group {i}
  fields as G0REVNP0
{0x5B4+0x400*i} G{i}REVNP1 32-bit (i=8..11) — Result Event Node Pointer Reg. 1, Group {i}
  fields as G0REVNP1
{0x5C0+0x400*i} G{i}SEVNP 32-bit (i=8..11) — Source Event Node Pointer Reg., Group {i}
  fields as G0SEVNP
{0x5C8+0x400*i} G{i}SRACT 32-bit wo (i=8..11) — Service Request Software Activation Trigger, Group {i}
  fields as G0SRACT
{0x5F0+0x400*i} G{i}EMUXCTR 32-bit (i=8..11) — External Multiplexer Control Reg., Group {i}
  fields as G0EMUXCTR
{0x5F4+0x400*i} G{i}EMUXCS 32-bit (i=8..11) — Ext. Multiplexer Channel Select Reg., Group {i}
  [15:0] EMUXCH — External Multiplexer Channel Select - EMUXCH
{0x5F8+0x400*i} G{i}VFR 32-bit (i=8..11) — Valid Flag Register, Group {i}
  [n] VF{n} (n=0..15) — Valid Flag of Result Register x - VF{n}
{0x2600+4i} G8CHCTR{i} 32-bit (i=0..15) — Group 8, Channel {i} Control Register
  fields as G0CHCTR0
{0x2680+4i} G8RCR{i} 32-bit (i=0..15) — Group 8 Result Control Register {i}
  fields as G0RCR0
{0x2700+4i} G8RES{i} 32-bit (i=0..15) — Group 8 Result Register {i}
  fields as G0RES0
{0x2780+4i} G8RESD{i} 32-bit ro (i=0..15) — Group 8 Result Reg. {i}, Debug
  fields as G0RESD0
{0x2A00+4i} G9CHCTR{i} 32-bit (i=0..15) — Group 9, Channel {i} Control Register
  fields as G0CHCTR0
{0x2A80+4i} G9RCR{i} 32-bit (i=0..15) — Group 9 Result Control Register {i}
  fields as G0RCR0
{0x2B00+4i} G9RES{i} 32-bit (i=0..15) — Group 9 Result Register {i}
  fields as G0RES0
{0x2B80+4i} G9RESD{i} 32-bit ro (i=0..15) — Group 9 Result Reg. {i}, Debug
  fields as G0RESD0
{0x2E00+4i} G10CHCTR{i} 32-bit (i=0..15) — Group 10, Channel {i} Control Register
  fields as G0CHCTR0
{0x2E80+4i} G10RCR{i} 32-bit (i=0..15) — Group 10 Result Control Register {i}
  fields as G0RCR0
{0x2F00+4i} G10RES{i} 32-bit (i=0..15) — Group 10 Result Register {i}
  fields as G0RES0
{0x2F80+4i} G10RESD{i} 32-bit ro (i=0..15) — Group 10 Result Reg. {i}, Debug
  fields as G0RESD0
{0x3200+4i} G11CHCTR{i} 32-bit (i=0..15) — Group 11, Channel {i} Control Register
  fields as G0CHCTR0
{0x3280+4i} G11RCR{i} 32-bit (i=0..15) — Group 11 Result Control Register {i}
  fields as G0RCR0
{0x3300+4i} G11RES{i} 32-bit (i=0..15) — Group 11 Result Register {i}
  fields as G0RES0
{0x3380+4i} G11RESD{i} 32-bit ro (i=0..15) — Group 11 Result Reg. {i}, Debug
  fields as G0RESD0
{0x3400+0x100*i} FC{i}FCCTRL 32-bit reset 0xC20 (i=0..3) — Fast Compare Control Register, FC Channel {i}
  [31] XTWC wo — Write Control for Trigger/Gate Configuration - XTWC
  [30:26] FCCHNR — Fast Compare Channel: Cannel Number - FCCHNR
  [25:24] GTMODE — Gate Operating Mode - GTMODE
  [23] XTPOL — External Trigger Polarity - XTPOL
  [22:21] XTMODE — Trigger Operating Mode - XTMODE
  [20] XTLVL ro — External Trigger Level - XTLVL
  [19:16] XTSEL — External Trigger Input Selection - XTSEL
  [15] CPWC wo — Write Control for Control Parameters - CPWC
  [14:10] DIVA — Divider Factor for the Analog Internal Clock - DIVA
  [9:8] CHEVMODE — Channel Event Mode - CHEVMODE
  [7:6] AIPF — Analog Input Precharge Enable for Fast Comparisons - AIPF
  [5] RPE — Reference Precharge Enable - RPE
  [4:0] STCF — Sample Time Control for Fast Comparisons - STCF
{0x3404+0x100*i} FC{i}FCM 32-bit (i=0..3) — Fast Compare Mode Register, FC Channel {i}
  [31:22] FCREF — Fast Compare Reference Value - FCREF
  [21] FCMWC wo — Write Control for Fast Compare Mode Configuration - FCMWC
  [20] SSE — Sample Synchronization Enable - SSE
  [19:18] AUE — Automatic Update Enable - AUE
  [17:16] SRG — Service Request Generation - SRG
  [15:8] FCTRIV — Fast Compare Trigger Interval - FCTRIV
  [7:6] ACSD — Analog Clock Synchronization Delay - ACSD
  [5] ANON — Analog Converter Control - ANON
  [4] FCRDIR — Fast Compare Ramp Direction - FCRDIR
  [3:2] RUNRAMP — Run Control for Ramp - RUNRAMP
  [1:0] RUNCOMP — Run Control for Compare Channel - RUNCOMP
{0x3408+0x100*i} FC{i}FCRAMP0 32-bit (i=0..3) — Fast Compare Ramp Register 0, FC Channel {i}
  [31] FSWC wo — Write Control for Fast Compare Stepwidth - FSWC
  [23:16] FCRSTEP — Fast Compare Ramp Step Width - FCRSTEP
  [9:0] FCRCOMPA — Fast Compare Ramp Compare Value A - FCRCOMPA
{0x340C+0x100*i} FC{i}FCRAMP1 32-bit (i=0..3) — Fast Compare Ramp Register 1, FC Channel {i}
  [9:0] FCRCOMPB — Fast Compare Ramp Compare Value B - FCRCOMPB
{0x3420+0x100*i} FC{i}FCBFL 32-bit (i=0..3) — Boundary Flag Register, FC Channel {i}
  [31] VF ro — Valid Flag - VF
  [28] FCR ro — Fast Compare Result - FCR
  [27:24] BFLNP — Boundary Flag Node Pointer
  [17] BFV — Boundary Flag Value - BFV
  [16] BFM — Boundary Flag Mode Control - BFM
  [13:12] BFS wo — Boundary Flag Software Control - BFS
  [8] BFI — Boundary Flag Inversion Control - BFI
  [4] BFA — Boundary Flag Activation Select - BFA
  [0] BFL ro — Boundary Flag - BFL
{0x3424+0x100*i} FC{i}FCHYST 32-bit (i=0..3) — Fast Comp. Hysteresis Register, FC Channel {i}
  [27:18] DELTAPLUS — Upper Delta Value - DELTAPLUS
  [11:2] DELTAMINUS — Lower Delta Value - DELTAMINUS
